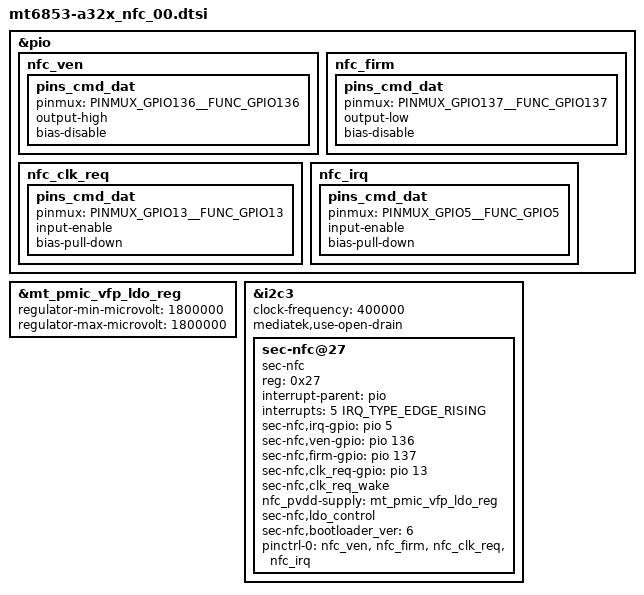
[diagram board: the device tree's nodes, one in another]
/* #include "../nfc_lsi.dtsi" */                     /* From nfc_lsi.py */
/*
 * This program is free software; you can redistribute it and/or modify
 * it under the terms of the GNU General Public License version 2 and
 * only version 2 as published by the Free Software Foundation.
 *
 * This program is distributed in the hope that it will be useful,
 * but WITHOUT ANY WARRANTY; without even the implied warranty of
 * MERCHANTABILITY or FITNESS FOR A PARTICULAR PURPOSE.  See the
 * GNU General Public License for more details.
 */

&pio {
	nfc_ven: nfc_ven {
		pins_cmd_dat {
			pinmux = <PINMUX_GPIO136__FUNC_GPIO136>;
			output-high;
			bias-disable;
		};
	};

	nfc_firm: nfc_firm {
		pins_cmd_dat {
			pinmux = <PINMUX_GPIO137__FUNC_GPIO137>;
			output-low;
			bias-disable;
		};
	};

	nfc_clk_req: nfc_clk_req {
		pins_cmd_dat {
			pinmux = <PINMUX_GPIO13__FUNC_GPIO13>;
			input-enable;
			bias-pull-down;
		};
	};

	nfc_irq: nfc_irq {
		pins_cmd_dat {
			pinmux = <PINMUX_GPIO5__FUNC_GPIO5>;
			input-enable;
			bias-pull-down;
		};
	};
};

&mt_pmic_vfp_ldo_reg {
	regulator-min-microvolt = <1800000>;
	regulator-max-microvolt = <1800000>;
};

&i2c3 {
	status = "ok";
	clock-frequency = <400000>;
	mediatek,use-open-drain;
	sec-nfc@27 {
		compatible = "sec-nfc";
		reg = <0x27>;
		interrupt-parent = <&pio>;
		interrupts = <5 IRQ_TYPE_EDGE_RISING>;
		sec-nfc,irq-gpio = <&pio 5 0>;
		sec-nfc,ven-gpio = <&pio 136 0>;
		sec-nfc,firm-gpio = <&pio 137 0>;
		sec-nfc,clk_req-gpio = <&pio 13 0>;
		sec-nfc,clk_req_wake;
		nfc_pvdd-supply = <&mt_pmic_vfp_ldo_reg>;
		sec-nfc,ldo_control;
		sec-nfc,bootloader_ver = <6>;
		/*sec-nfc,irq_all_trigger;*/
		pinctrl-names = "default";
		pinctrl-0 = <&nfc_ven &nfc_firm &nfc_clk_req &nfc_irq>;
	};
};
